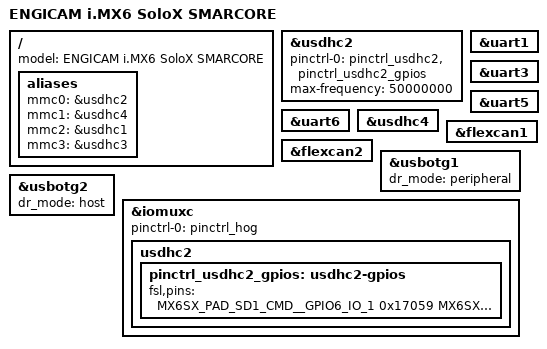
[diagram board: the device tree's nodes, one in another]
/*
 * Copyright (C) 2015 Freescale Semiconductor, Inc.
 *
 * This program is free software; you can redistribute it and/or modify
 * it under the terms of the GNU General Public License version 2 as
 * published by the Free Software Foundation.
 */

#include "imx6sx-smarcore.dtsi"

/ {
	model = "ENGICAM i.MX6 SoloX SMARCORE";

  aliases 
  {
		mmc0 = &usdhc2;
		mmc1 = &usdhc4;
		mmc2 = &usdhc1;
		mmc3 = &usdhc3;
	};
	
};
      
&usdhc2 {
	pinctrl-names = "default";
	pinctrl-0 = <&pinctrl_usdhc2 &pinctrl_usdhc2_gpios>;
	status = "okay";
  max-frequency = <50000000>;
};

&uart1 {
  status = "okay";
};

&uart3 {
  status = "okay";
};

&uart5 {
  status = "okay";
};

&uart6 {
  status = "okay";
};

&usdhc4 {
  status = "okay";
};

&flexcan1 {
  status = "okay";
};

&flexcan2 {
  status = "okay";
};

&usbotg1 {
  dr_mode = "peripheral";
	status = "okay";
};

&usbotg2 {
  dr_mode = "host";
	status = "okay";
};

&iomuxc {
	pinctrl-names = "default";
	pinctrl-0 = <&pinctrl_hog>;

	usdhc2 {
		pinctrl_usdhc2_gpios: usdhc2-gpios {
			fsl,pins = <
				MX6SX_PAD_SD1_CMD__GPIO6_IO_1     0x17059       //SD2_PWR_EN
				MX6SX_PAD_LCD1_RESET__GPIO3_IO_27 0x17059       //SD2_CD
				MX6SX_PAD_GPIO1_IO07__GPIO1_IO_7  0x17059       //SD2_WP 
			>;
		};
	};
};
